# STM32H523 register map
File version: 1.2
CPU: CM33 r0p0, little endian, MPU, FPU, 4 interrupt priority bits
Registers are 32-bit, read-write, reset 0x0 unless marked. A register's access mark holds for its fields unless they carry their own. Offsets are from the block's base; [hi:lo] are bit positions; {n}, {i} and the like mark numbered series; 'fields as' and 'values as' point back to an identical list.

## EXTI — EXTI address block description
Base 0x44022000
Same registers: EXTI_S 0x54022000
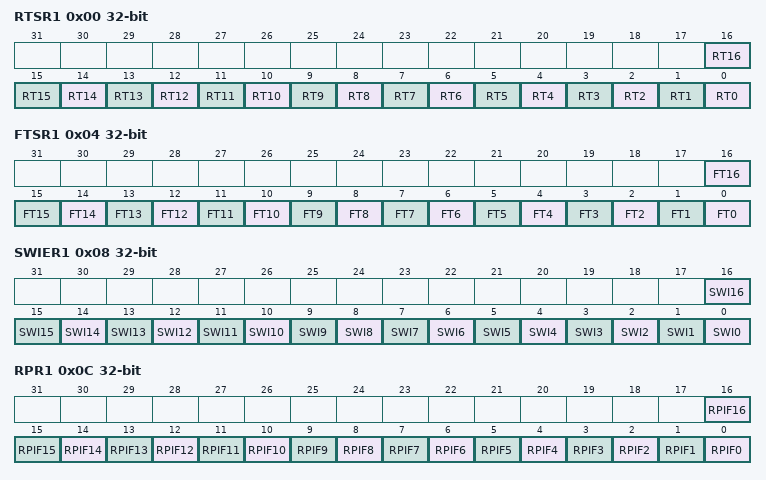
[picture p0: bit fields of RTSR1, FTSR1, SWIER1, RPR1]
0x00 RTSR1 — EXTI rising trigger selection register
  [all] fields
    0=Disabled (Rising edge trigger is disabled); 1=Enabled (Rising edge trigger is enabled)
  [n] RT{n} (n=0..16) — Rising trigger event configuration bit of configurable event input x
0x04 FTSR1 — EXTI falling trigger selection register
  [all] fields
    0=Disabled (Falling edge trigger is disabled); 1=Enabled (Falling edge trigger is enabled)
  [n] FT{n} (n=0..16) — Falling trigger event configuration bit of configurable event input x
0x08 SWIER1 — EXTI software interrupt event register
  [all] fields
    on write: 1=Pend (Generates an interrupt request)
  [n] SWI{n} (n=0..16) — Software interrupt on event x
0x0C RPR1 — EXTI rising edge pending register
  [all] fields
    on read: 0=NotPending (No trigger request occurred); 1=Pending (Selected trigger request occurred) | on write: 1=Clears pending bit
  [n] RPIF{n} write-1-clears (n=0..16) — configurable event inputs x rising edge pending bit
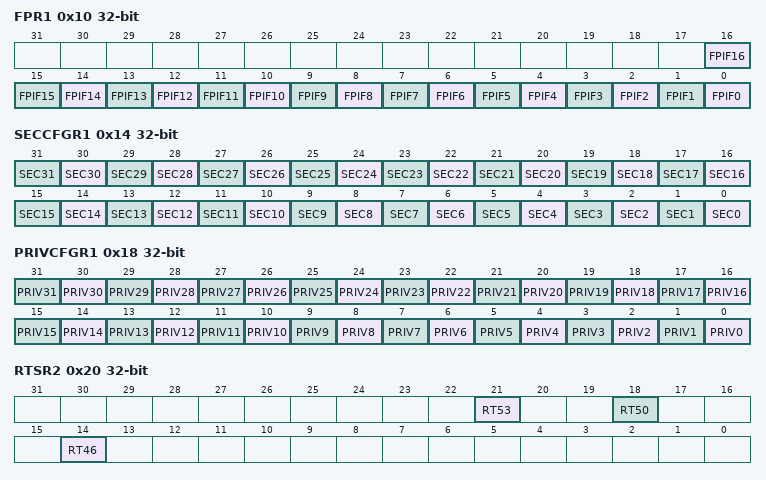
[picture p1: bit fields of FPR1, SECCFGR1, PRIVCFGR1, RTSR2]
0x10 FPR1 — EXTI falling edge pending register
  [all] fields
    values as the fields of RPR1
  [n] FPIF{n} write-1-clears (n=0..16) — configurable event inputs x falling edge pending bit
0x14 SECCFGR1 — EXTI security configuration register
  [n] SEC{n} (n=0..31) — Security enable on event input x
0x18 PRIVCFGR1 — EXTI privilege configuration register
  [all] fields
    0=Unprivileged (Event privilege disabled); 1=Privileged (Event privilege enabled)
  [n] PRIV{n} (n=0..31) — Security enable on event input x
0x20 RTSR2 — EXTI rising trigger selection register 2
  [all] fields
    values as the fields of RTSR1
  [21] RT53 — Rising trigger event configuration bit of configurable event input x
  [18] RT50 — Rising trigger event configuration bit of configurable event input xless thansup>(1)less than/sup>
  [14] RT46 — Rising trigger event configuration bit of configurable event input xless thansup>(1)less than/sup>
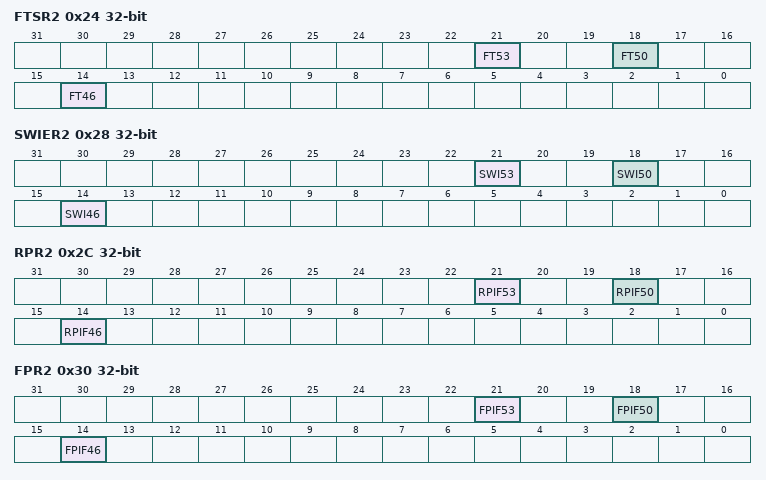
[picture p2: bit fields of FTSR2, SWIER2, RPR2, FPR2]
0x24 FTSR2 — EXTI falling trigger selection register 2
  [all] fields
    values as the fields of FTSR1
  [21] FT53 — Falling trigger event configuration bit of configurable event input x
  [18] FT50 — Falling trigger event configuration bit of configurable event input x less thansup>(1)less than/sup>
  [14] FT46 — Falling trigger event configuration bit of configurable event input x less thansup>(1)less than/sup>
0x28 SWIER2 — EXTI software interrupt event register 2
  [all] fields
    on write: 1=Pend (Generates an interrupt request)
  [21] SWI53 — Software interrupt on event x
  [18] SWI50 — Software interrupt on event x
  [14] SWI46 — Software interrupt on event x
0x2C RPR2 — EXTI rising edge pending register 2
  [all] fields
    values as the fields of RPR1
  [21] RPIF53 write-1-clears — configurable event inputs x rising edge pending bit
  [18] RPIF50 write-1-clears — configurable event inputs x rising edge pending bit
  [14] RPIF46 write-1-clears — configurable event inputs x rising edge pending bit
0x30 FPR2 — EXTI falling edge pending register 2
  [all] fields
    values as the fields of RPR1
  [21] FPIF53 write-1-clears — configurable event inputs x falling edge pending bit
  [18] FPIF50 write-1-clears — configurable event inputs x falling edge pending bit
  [14] FPIF46 write-1-clears — configurable event inputs x falling edge pending bit
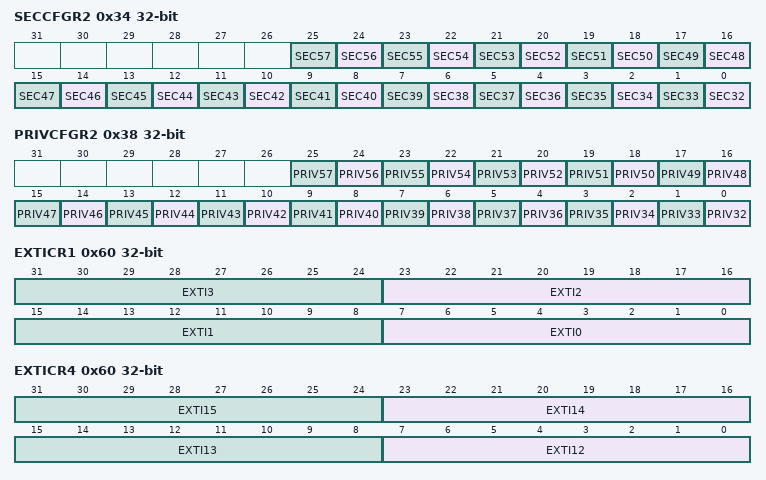
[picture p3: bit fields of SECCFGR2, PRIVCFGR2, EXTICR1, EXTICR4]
0x34 SECCFGR2 — EXTI security configuration register 2
  [n-32] SEC{n} (n=32..57) — Security enable on event input x
0x38 PRIVCFGR2 — EXTI privilege configuration register 2
  [all] fields
    values as the fields of PRIVCFGR1
  [n-32] PRIV{n} (n=32..57) — Security enable on event input x
0x60 EXTICR1 — EXTI external interrupt selection register
  [8n+7:8n] EXTI{n} (n=0..3) — EXTI{n} GPIO port selection
0x60 EXTICR4 (alternate view of EXTICR1) — EXTI external interrupt selection register
  [8n-89:8n-96] EXTI{n} (n=12..15) — EXTI{n} GPIO port selection
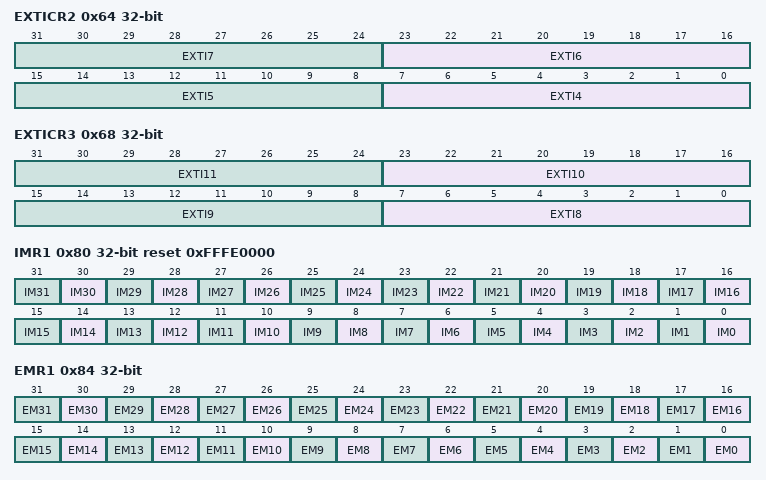
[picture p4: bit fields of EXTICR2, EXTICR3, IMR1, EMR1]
0x64 EXTICR2 — EXTI external interrupt selection register
  [8n-25:8n-32] EXTI{n} (n=4..7) — EXTI{n} GPIO port selection
0x68 EXTICR3 — EXTI external interrupt selection register
  [8n-57:8n-64] EXTI{n} (n=8..11) — EXTI{n} GPIO port selection
0x70 LOCKR — EXTI lock register
  [0] LOCK — Global security and privilege configuration registers (EXTI_SECCFGR and EXTI_PRIVCFGR) lock
0x80 IMR1 reset 0xFFFE0000 — EXTI CPU wake-up with interrupt mask register
  [all] fields
    0=Masked (Interrupt request line is masked); 1=Unmasked (Interrupt request line is unmasked)
  [n] IM{n} (n=0..31) — CPU wake-up with interrupt mask on event input x
0x84 EMR1 — EXTI CPU wake-up with event mask register
  [all] fields
    0=Masked (Event request line is masked); 1=Unmasked (Event request line is unmasked)
  [n] EM{n} (n=0..31) — CPU wake-up with event generation mask on event input x
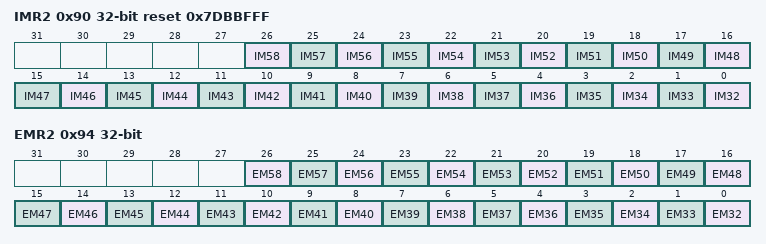
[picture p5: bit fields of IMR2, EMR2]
0x90 IMR2 reset 0x7DBBFFF — EXTI CPU wake-up with interrupt mask register 2
  [all] fields
    values as the fields of IMR1
  [n-32] IM{n} (n=32..58) — CPU wake-up with interrupt mask on event input x
0x94 EMR2 — EXTI CPU wake-up with event mask register 2
  [all] fields
    values as the fields of EMR1
  [n-32] EM{n} (n=32..58) — CPU wake-up with event generation mask on event input x
